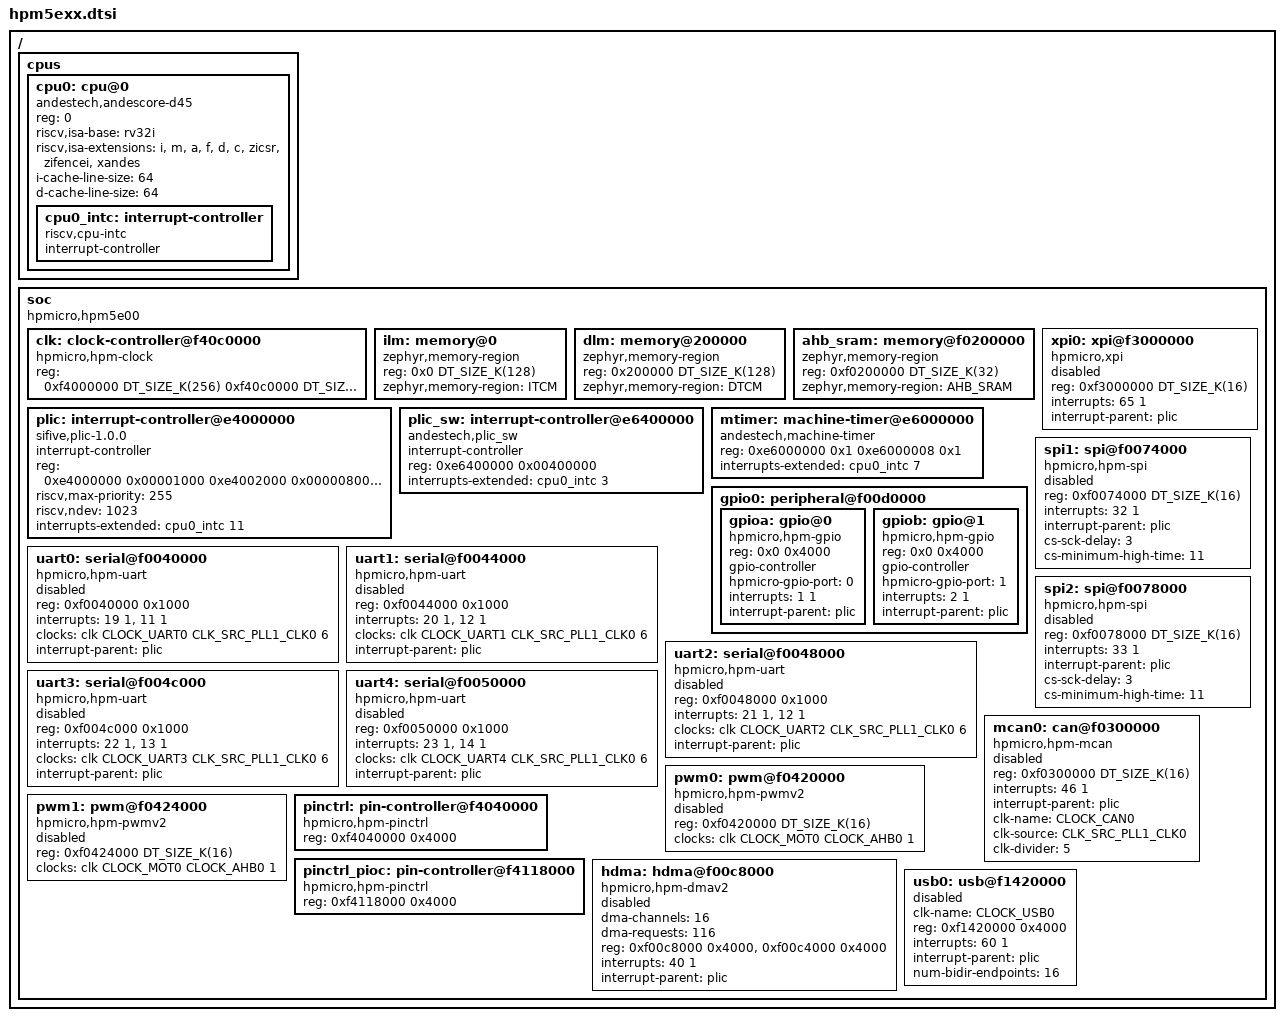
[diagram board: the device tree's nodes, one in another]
/*
 * Copyright (c) 2026 HPMicro
 * SPDX-License-Identifier: Apache-2.0
 */

/dts-v1/;
#include <zephyr/dt-bindings/gpio/gpio.h>
#include <dt-bindings/clock/hpm5e3y-clocks.h>
#include <mem.h>
#include <freq.h>

/ {
	#address-cells = <1>;
	#size-cells = <1>;

	cpus {
		#address-cells = <1>;
		#size-cells = <0>;
		cpu0: cpu@0 {
			compatible = "andestech,andescore-d45", "riscv";
			reg = <0>;
			status = "okay";
			riscv,isa-base = "rv32i";
			riscv,isa-extensions = "i", "m", "a", "f", "d", "c", "zicsr", "zifencei", "xandes";
			i-cache-line-size = <64>;
			d-cache-line-size = <64>;

			cpu0_intc: interrupt-controller {
				compatible = "riscv,cpu-intc";
				#address-cells = <0>;
				#interrupt-cells = <1>;
				interrupt-controller;
			};
		};
	};

	soc {
		#address-cells = <1>;
		#size-cells = <1>;
		compatible = "hpmicro,hpm5e00";
		ranges;

		clk: clock-controller@f40c0000 {
			compatible = "hpmicro,hpm-clock";
			reg = <0xf4000000 DT_SIZE_K(256)
				0xf40c0000 DT_SIZE_K(16)>;
			reg-names = "sysctl", "pll";
			#clock-cells = <3>;
			status = "okay";
		};

		ilm: memory@0 {
			compatible = "zephyr,memory-region";
			reg = <0x0 DT_SIZE_K(128)>;
			zephyr,memory-region = "ITCM";
		};

		dlm: memory@200000 {
			compatible = "zephyr,memory-region";
			reg = <0x200000 DT_SIZE_K(128)>;
			zephyr,memory-region = "DTCM";
		};

		ahb_sram: memory@f0200000 {
			compatible = "zephyr,memory-region";
			reg = <0xf0200000 DT_SIZE_K(32)>;
			zephyr,memory-region = "AHB_SRAM";
		};

		plic: interrupt-controller@e4000000 {
			compatible = "sifive,plic-1.0.0";
			#address-cells = <1>;
			#interrupt-cells = <2>;
			interrupt-controller;
			reg = <	0xe4000000 0x00001000
				0xe4002000 0x00000800
				0xe4200000 0x00010000 >;
			reg-names = "prio", "irq_en", "reg";
			riscv,max-priority = <255>;
			riscv,ndev = <1023>;
			interrupts-extended = <&cpu0_intc 11>;
		};

		plic_sw: interrupt-controller@e6400000 {
			compatible = "andestech,plic_sw";
			#address-cells = <1>;
			#interrupt-cells = <2>;
			interrupt-controller;
			reg = <0xe6400000 0x00400000>;
			interrupts-extended = <&cpu0_intc 3>;
		};

		mtimer: machine-timer@e6000000 {
			compatible = "andestech,machine-timer";
			reg = <0xe6000000 0x1
				0xe6000008 0x1>;
			interrupts-extended = <&cpu0_intc 7>;
		};

		xpi0: xpi@f3000000 {
			compatible = "hpmicro,xpi";
			reg = <0xf3000000 DT_SIZE_K(16)>;
			interrupts = <65 1>;
			interrupt-parent = <&plic>;
			#address-cells = <1>;
			#size-cells = <1>;
			status = "disabled";
		};

		gpio0: peripheral@f00d0000 {
			#address-cells = <1>;
			#size-cells = <1>;
			ranges = <0x0 0xf00d0000 DT_SIZE_K(16)>;
		};

		uart0: serial@f0040000 {
			compatible = "hpmicro,hpm-uart";
			reg = <0xf0040000 0x1000>;
			interrupts = <19 1>, <11 1>;
			interrupt-names = "uart", "idletimer";
			clocks = <&clk CLOCK_UART0 CLK_SRC_PLL1_CLK0 6>;
			interrupt-parent = <&plic>;
			status = "disabled";
		};

		uart1: serial@f0044000 {
			compatible = "hpmicro,hpm-uart";
			reg = <0xf0044000 0x1000>;
			interrupts = <20 1>, <12 1>;
			interrupt-names = "uart", "idletimer";
			clocks = <&clk CLOCK_UART1 CLK_SRC_PLL1_CLK0 6>;
			interrupt-parent = <&plic>;
			status = "disabled";
		};

		uart2: serial@f0048000 {
			compatible = "hpmicro,hpm-uart";
			reg = <0xf0048000 0x1000>;
			interrupts = <21 1>, <12 1>;
			interrupt-names = "uart", "idletimer";
			clocks = <&clk CLOCK_UART2 CLK_SRC_PLL1_CLK0 6>;
			interrupt-parent = <&plic>;
			status = "disabled";
		};

		uart3: serial@f004c000 {
			compatible = "hpmicro,hpm-uart";
			reg = <0xf004c000 0x1000>;
			interrupts = <22 1>, <13 1>;
			interrupt-names = "uart", "idletimer";
			clocks = <&clk CLOCK_UART3 CLK_SRC_PLL1_CLK0 6>;
			interrupt-parent = <&plic>;
			status = "disabled";
		};

		uart4: serial@f0050000 {
			compatible = "hpmicro,hpm-uart";
			reg = <0xf0050000 0x1000>;
			interrupts = <23 1>, <14 1>;
			interrupt-names = "uart", "idletimer";
			clocks = <&clk CLOCK_UART4 CLK_SRC_PLL1_CLK0 6>;
			interrupt-parent = <&plic>;
			status = "disabled";
		};

		spi1: spi@f0074000 {
			compatible = "hpmicro,hpm-spi";
			reg = <0xf0074000 DT_SIZE_K(16)>;
			interrupts = <32 1>;
			interrupt-parent = <&plic>;
			status = "disabled";
			#address-cells = <1>;
			#size-cells = <0>;
			cs-sck-delay = <3>;
			cs-minimum-high-time = <11>;
		};

		spi2: spi@f0078000 {
			compatible = "hpmicro,hpm-spi";
			reg = <0xf0078000 DT_SIZE_K(16)>;
			interrupts = <33 1>;
			interrupt-parent = <&plic>;
			status = "disabled";
			#address-cells = <1>;
			#size-cells = <0>;
			cs-sck-delay = <3>;
			cs-minimum-high-time = <11>;
		};

		mcan0: can@f0300000 {
			compatible = "hpmicro,hpm-mcan";
			reg = <0xf0300000 DT_SIZE_K(16)>;
			interrupts = <46 1>;
			interrupt-parent = <&plic>;
			clk-name = <CLOCK_CAN0>;
			clk-source = <CLK_SRC_PLL1_CLK0>;
			clk-divider = <5>;
			status = "disabled";
		};

		pwm0: pwm@f0420000 {
			compatible = "hpmicro,hpm-pwmv2";
			reg = <0xf0420000 DT_SIZE_K(16)>;
			clocks = <&clk CLOCK_MOT0 CLOCK_AHB0 1>;
			status = "disabled";
			#pwm-cells = <3>;
		};

		pwm1: pwm@f0424000 {
			compatible = "hpmicro,hpm-pwmv2";
			reg = <0xf0424000 DT_SIZE_K(16)>;
			clocks = <&clk CLOCK_MOT0 CLOCK_AHB0 1>;
			status = "disabled";
			#pwm-cells = <3>;
		};

		pinctrl: pin-controller@f4040000 {
			compatible = "hpmicro,hpm-pinctrl";
			reg = <0xf4040000 0x4000>;
			status = "okay";
		};

		pinctrl_pioc: pin-controller@f4118000 {
			compatible = "hpmicro,hpm-pinctrl";
			reg = <0xf4118000 0x4000>;
			status = "okay";
		};

		hdma: hdma@f00c8000 {
			#dma-cells = <2>;
			compatible = "hpmicro,hpm-dmav2";
			dma-channels = <16>;
			dma-requests = <116>;
			reg = <0xf00c8000 0x4000>,
				<0xf00c4000 0x4000>; /* DMAMUX base */
			interrupts = <40 1>;
			interrupt-parent = <&plic>;
			status = "disabled";
		};

		usb0: usb@f1420000 {
			clk-name = <CLOCK_USB0>;
			reg = <0xf1420000 0x4000>;
			interrupts = <60 1>;
			interrupt-parent = <&plic>;
			num-bidir-endpoints = <16>;
			status = "disabled";
		};
	};
};

&gpio0 {
	gpioa: gpio@0 {
		compatible = "hpmicro,hpm-gpio";
		reg = <0x0 0x4000>;
		gpio-controller;
		#gpio-cells = <2>;
		hpmicro-gpio-port = <0>;
		interrupts = <1 1>;
		interrupt-parent = <&plic>;
	};

	gpiob: gpio@1 {
		compatible = "hpmicro,hpm-gpio";
		reg = <0x0 0x4000>;
		gpio-controller;
		#gpio-cells = <2>;
		hpmicro-gpio-port = <1>;
		interrupts = <2 1>;
		interrupt-parent = <&plic>;
	};

};
